# ESP8266 register map
File version: 1.0
CPU: Xtensa LX106 1, little endian, no MPU, FPU, 3 interrupt priority bits
Registers are 32-bit, read-write, reset 0x0 unless marked. A register's access mark holds for its fields unless they carry their own. Offsets are from the block's base; [hi:lo] are bit positions; {n}, {i} and the like mark numbered series; 'fields as' and 'values as' point back to an identical list.

## I2S
Base 0x60000E00
0x00 I2STXFIFO
  [31:0] Register
0x04 I2SRXFIFO
  [31:0] Register
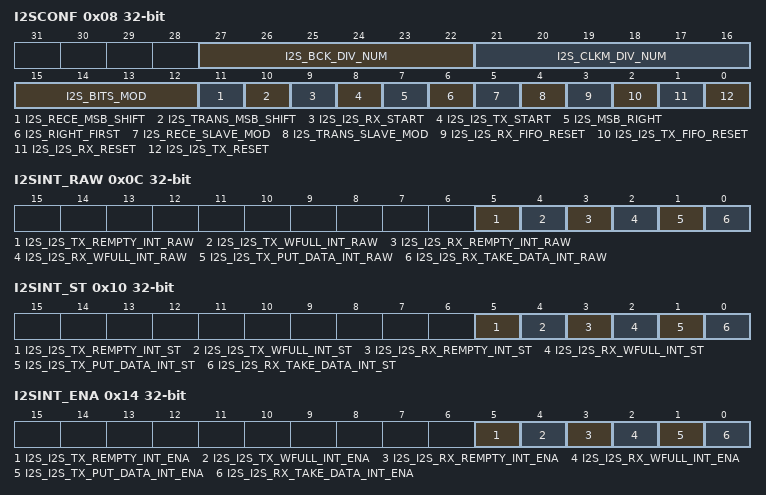
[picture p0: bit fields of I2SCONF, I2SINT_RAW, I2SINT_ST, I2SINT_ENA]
0x08 I2SCONF
  [27:22] I2S_BCK_DIV_NUM, [21:16] I2S_CLKM_DIV_NUM, [15:12] I2S_BITS_MOD, [11] I2S_RECE_MSB_SHIFT, [10] I2S_TRANS_MSB_SHIFT, [9] I2S_I2S_RX_START, [8] I2S_I2S_TX_START, [7] I2S_MSB_RIGHT, [6] I2S_RIGHT_FIRST, [5] I2S_RECE_SLAVE_MOD, [4] I2S_TRANS_SLAVE_MOD, [3] I2S_I2S_RX_FIFO_RESET, [2] I2S_I2S_TX_FIFO_RESET, [1] I2S_I2S_RX_RESET, [0] I2S_I2S_TX_RESET
0x0C I2SINT_RAW
  [5] I2S_I2S_TX_REMPTY_INT_RAW, [4] I2S_I2S_TX_WFULL_INT_RAW, [3] I2S_I2S_RX_REMPTY_INT_RAW, [2] I2S_I2S_RX_WFULL_INT_RAW, [1] I2S_I2S_TX_PUT_DATA_INT_RAW, [0] I2S_I2S_RX_TAKE_DATA_INT_RAW
0x10 I2SINT_ST
  [5] I2S_I2S_TX_REMPTY_INT_ST, [4] I2S_I2S_TX_WFULL_INT_ST, [3] I2S_I2S_RX_REMPTY_INT_ST, [2] I2S_I2S_RX_WFULL_INT_ST, [1] I2S_I2S_TX_PUT_DATA_INT_ST, [0] I2S_I2S_RX_TAKE_DATA_INT_ST
0x14 I2SINT_ENA
  [5] I2S_I2S_TX_REMPTY_INT_ENA, [4] I2S_I2S_TX_WFULL_INT_ENA, [3] I2S_I2S_RX_REMPTY_INT_ENA, [2] I2S_I2S_RX_WFULL_INT_ENA, [1] I2S_I2S_TX_PUT_DATA_INT_ENA, [0] I2S_I2S_RX_TAKE_DATA_INT_ENA
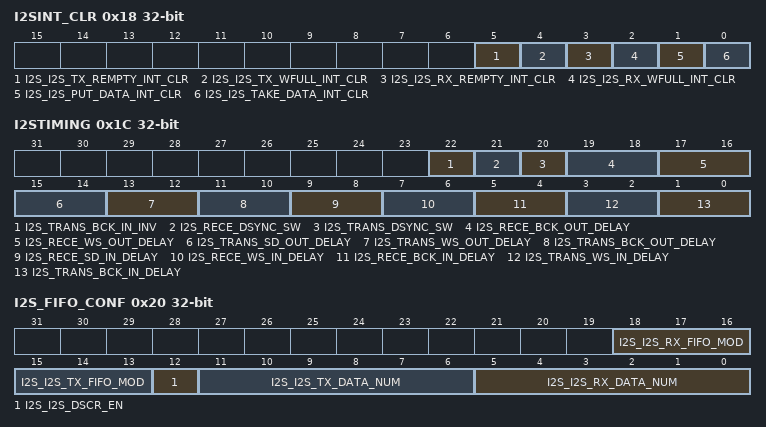
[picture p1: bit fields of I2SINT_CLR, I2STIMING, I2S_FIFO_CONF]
0x18 I2SINT_CLR
  [5] I2S_I2S_TX_REMPTY_INT_CLR, [4] I2S_I2S_TX_WFULL_INT_CLR, [3] I2S_I2S_RX_REMPTY_INT_CLR, [2] I2S_I2S_RX_WFULL_INT_CLR, [1] I2S_I2S_PUT_DATA_INT_CLR, [0] I2S_I2S_TAKE_DATA_INT_CLR
0x1C I2STIMING
  [22] I2S_TRANS_BCK_IN_INV, [21] I2S_RECE_DSYNC_SW, [20] I2S_TRANS_DSYNC_SW, [19:18] I2S_RECE_BCK_OUT_DELAY, [17:16] I2S_RECE_WS_OUT_DELAY, [15:14] I2S_TRANS_SD_OUT_DELAY, [13:12] I2S_TRANS_WS_OUT_DELAY, [11:10] I2S_TRANS_BCK_OUT_DELAY, [9:8] I2S_RECE_SD_IN_DELAY, [7:6] I2S_RECE_WS_IN_DELAY, [5:4] I2S_RECE_BCK_IN_DELAY, [3:2] I2S_TRANS_WS_IN_DELAY, [1:0] I2S_TRANS_BCK_IN_DELAY
0x20 I2S_FIFO_CONF
  [18:16] I2S_I2S_RX_FIFO_MOD, [15:13] I2S_I2S_TX_FIFO_MOD, [12] I2S_I2S_DSCR_EN, [11:6] I2S_I2S_TX_DATA_NUM, [5:0] I2S_I2S_RX_DATA_NUM
0x24 I2SRXEOF_NUM
  [31:0] I2S_I2S_RX_EOF_NUM
0x28 I2SCONF_SIGLE_DATA
  [31:0] I2S_I2S_SIGLE_DATA

## IO_MUX
Base 0x60000800
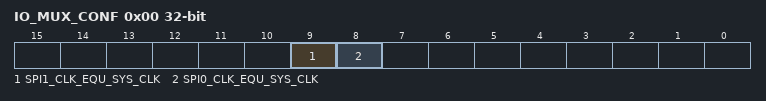
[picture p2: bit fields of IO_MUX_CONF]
0x00 IO_MUX_CONF
  [9] SPI1_CLK_EQU_SYS_CLK, [8] SPI0_CLK_EQU_SYS_CLK
0x04 IO_MUX_MTDI access not given
  [8] FUNCTION_SELECT_HIGH_BIT — configures IO_MUX function, upper bit
  [7] PULLUP — configures pull up
  [5:4] FUNCTION_SELECT_LOW_BITS — configures IO_MUX function, bottom 2 bits
  [3] SLEEP_PULLUP — configures pull up during sleep mode
  [31:0] Register rw
  [0] SLEEP_ENABLE — configures output enable during sleep mode
0x08 IO_MUX_MTCK access not given
  fields as IO_MUX_MTDI
0x0C IO_MUX_MTMS access not given
  fields as IO_MUX_MTDI
0x10 IO_MUX_MTDO access not given
  fields as IO_MUX_MTDI
0x14 IO_MUX_U0RXD access not given
  fields as IO_MUX_MTDI
0x18 IO_MUX_U0TXD access not given
  fields as IO_MUX_MTDI
0x1C IO_MUX_SD_CLK access not given
  fields as IO_MUX_MTDI
{0x20+4i} IO_MUX_SD_DATA{i} access not given (i=0..3)
  fields as IO_MUX_MTDI
0x30 IO_MUX_SD_CMD access not given
  fields as IO_MUX_MTDI
0x34 IO_MUX_GPIO0 access not given
  fields as IO_MUX_MTDI
0x38 IO_MUX_GPIO2 access not given
  fields as IO_MUX_MTDI
0x3C IO_MUX_GPIO4 access not given
  fields as IO_MUX_MTDI
0x40 IO_MUX_GPIO5 access not given
  fields as IO_MUX_MTDI

## RTC
Base 0x60000700
0x14 RTC_STATE1
  [31:0] Register
0x30 RTC_STORE0
  [31:0] Register
0x68 RTC_GPIO_OUT
0x74 RTC_GPIO_ENABLE
0x8C RTC_GPIO_IN_DATA
0x90 RTC_GPIO_CONF
0xA0 PAD_XPD_DCDC_CONF

## TIMER
Base 0x60000600
0x00 FRC1_LOAD — the load value into the counter
  [22:0] frc1_load_value
0x04 FRC1_COUNT ro — the current value of the counter. It is a decreasingcounter.
  [22:0] frc1_count
0x08 FRC1_CTRL access per field
  [8] frc1_int ro — the status of the interrupt, when the count isdereased to zero
  [7] timer_enable rw — Enable or disable the timer
  [6] rollover rw — Automatically reload when the counter hits zero
  [3:2] prescale_divider rw — Pre-scale divider for the timer
    0=devided_by_1 (divided by 1); 1=devided_by_16 (divided by 16); 2=devided_by_256 (divided by 256)
  [7:0] frc1_ctrl rw — bit[7]: timer enable, bit[6]: automatically reload, when the counter isequal to zero, bit[3:2]: prescale-divider, 0: divided by 1, 1: dividedby 16, 2 or 3: divided by 256, bit[0]: interrupt type, 0:edge, 1:level
  [0] interrupt_type rw — Configure the interrupt type
    0=edge; 1=level
0x0C FRC1_INT
  [0] frc1_int_clr_mask — write to clear the status of the interrupt, if theinterrupt type is "level"
0x20 FRC2_LOAD — the load value into the counter
  [31:0] frc2_load_value
0x24 FRC2_COUNT ro — the current value of the counter. It is a increasingcounter.
0x28 FRC2_CTRL access per field
  [8] frc2_int ro — the status of the interrupt, when the count is equal tothe alarm value
  [7] timer_enable rw — Enable or disable the timer
  [6] rollover rw — Automatically reload when the counter hits zero
  [3:2] prescale_divider rw — Pre-scale divider for the timer
    values as FRC1_CTRL.prescale_divider
  [7:0] frc2_ctrl rw — bit[7]: timer enable, bit[6]: automatically reload, when the counter isequal to zero, bit[3:2]: prescale-divider, 0: divided by 1, 1: dividedby 16, 2 or 3: divided by 256, bit[0]: interrupt type, 0:edge, 1:level
  [0] interrupt_type rw — Configure the interrupt type
    0=edge; 1=level
0x2C FRC2_INT
  [0] frc2_int_clr_mask — write to clear the status of the interrupt, if theinterrupt type is "level"
0x30 FRC2_ALARM — the alarm value for the counter

## WDT
Base 0x60000900
0x00 WDT_CTL access not given
  [5] unknown_5
  [4] unknown_4
  [3] unknown_3
  [2] stage_1_disable — Set to 1 to disable the stage 1 of the watchdog timer
  [1] stage_1_no_reset — When set to 1, and running in two-stage mode, it turns the watchdog into a single shot timer that doesn't reset the device.
  [31:0] Register rw
  [0] enable — Enable the watchdog timer.
0x04 WDT_OP — Reload value for stage 0
  [31:0] Register
0x08 WDT_OP_ND — Reload value for stage 1
  [31:0] Register
0x0C count — Watchdog clock cycle count
0x10 stage — The current watchdog stage
0x14 WDT_RST — Watchdog reset
  [31:0] Register
0x18 reset_stage — Watchdog stage reset

## RNG
Base 0x3FF20E44
0x00 rng ro

## RTCCNTL — Internal I2C registers
Base 0x60000D00
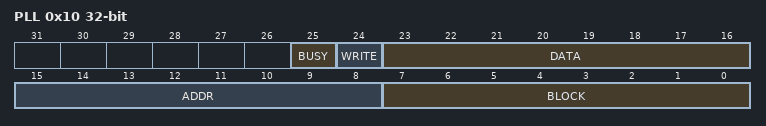
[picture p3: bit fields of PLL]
0x10 PLL — PLL I2C Register
  [25] BUSY — Ready
  [24] WRITE
  [23:16] DATA
  [15:8] ADDR — Address
  [7:0] BLOCK
